# MKW41Z4 register map
Vendor: Freescale Semiconductor, Inc.; Series: Kinetis_W; File version: 1.6
CPU: CM0PLUS r0p0, little endian, no MPU, no FPU, VTOR, 2 interrupt priority bits
Registers are 16-bit, read-write, no defined reset value unless marked. A register's access mark holds for its fields unless they carry their own. Offsets are from the block's base; [hi:lo] are bit positions; {n}, {i} and the like mark numbered series; 'fields as' and 'values as' point back to an identical list.

## TSI0 — Touch sense input
Base 0x40045000; register names take the prefix TSI0_
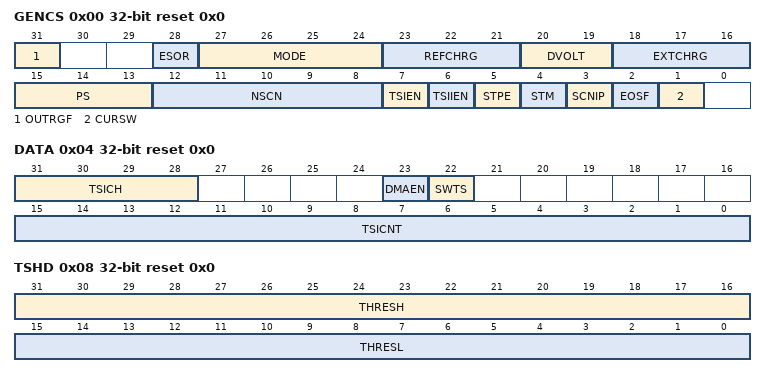
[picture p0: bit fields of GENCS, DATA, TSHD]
0x00 GENCS 32-bit reset 0x0 — TSI General Control and Status Register
  [31] OUTRGF — Out of Range Flag.
  [28] ESOR — End-of-scan or Out-of-Range Interrupt Selection
    0=Out-of-range interrupt is allowed; 1=End-of-scan interrupt is allowed
  [27:24] MODE — TSI analog modes setup and status bits.
    0=Set TSI in capacitive sensing(non-noise detection) mode; 4=Set TSI analog to work in single threshold noise detection mode and the frequency limitation circuit is disabled; 8=Set TSI analog to work in single threshold noise detection mode and the frequency limitation circuit is enabled to work in higher frequencies operations; 12=Set TSI analog to work in automatic noise detection mode
  [23:21] REFCHRG
    0=500 nA; 1=1 uA; 2=2 uA; 3=4 uA; 4=8 uA; 5=16 uA; 6=32 uA; 7=64 uA
  [20:19] DVOLT
    0=DV = 1.026 V; VP = 1.328 V; Vm = 0.302 V; 1=DV = 0.592 V; VP = 1.111 V; Vm = 0.519 V; 2=DV = 0.342 V; VP = 0.986 V; Vm = 0.644 V; 3=DV = 0.197 V; VP = 0.914 V; Vm = 0.716 V
  [18:16] EXTCHRG
    values as REFCHRG
  [15:13] PS
    0=Electrode Oscillator Frequency divided by 1; 1=Electrode Oscillator Frequency divided by 2; 2=Electrode Oscillator Frequency divided by 4; 3=Electrode Oscillator Frequency divided by 8; 4=Electrode Oscillator Frequency divided by 16; 5=Electrode Oscillator Frequency divided by 32; 6=Electrode Oscillator Frequency divided by 64; 7=Electrode Oscillator Frequency divided by 128
  [12:8] NSCN
    0=Once per electrode; 1=Twice per electrode; {v}={v+1} times per electrode (v=2..31)
  [7] TSIEN — Touch Sensing Input Module Enable
    0=TSI module disabled; 1=TSI module enabled
  [6] TSIIEN — Touch Sensing Input Interrupt Enable
    0=TSI interrupt is disabled; 1=TSI interrupt is enabled
  [5] STPE — TSI STOP Enable
    0=TSI is disabled when MCU goes into low power mode; 1=Allows TSI to continue running in all low power modes
  [4] STM — Scan Trigger Mode
    0=Software trigger scan; 1=Hardware trigger scan
  [3] SCNIP ro — Scan In Progress Status
    0=No scan in progress; 1=Scan in progress
  [2] EOSF — End of Scan Flag
    0=Scan not complete; 1=Scan complete
  [1] CURSW
    0=The current source pair are not swapped; 1=The current source pair are swapped
0x04 DATA 32-bit reset 0x0 — TSI DATA Register
  [31:28] TSICH
    {v}=Channel {v} (v=0..15)
  [23] DMAEN — DMA Transfer Enabled
    0=Interrupt is selected when the interrupt enable bit is set and the corresponding TSI events assert; 1=DMA transfer request is selected when the interrupt enable bit is set and the corresponding TSI events assert
  [22] SWTS wo — Software Trigger Start
    0=No effect; 1=Start a scan to determine which channel is specified by TSI_DATA[TSICH]
  [15:0] TSICNT ro — TSI Conversion Counter Value
0x08 TSHD 32-bit reset 0x0 — TSI Threshold Register
  [31:16] THRESH — TSI Wakeup Channel High-threshold
  [15:0] THRESL — TSI Wakeup Channel Low-threshold

## BTLE_RF_regs — BLE_RF
Base 0x4005B000
0x600 BLE_PART_ID ro reset 0x3 — BLUETOOTH LOW ENERGY PART ID
  [15:0] BLE_PART_ID
    0=Pre-production; 1=Pre-production; 2=KW40Z; 3=KW41Z
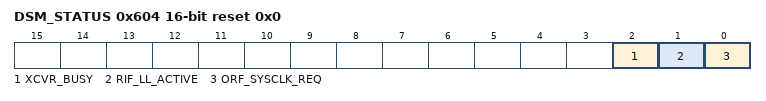
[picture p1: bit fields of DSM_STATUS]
0x604 DSM_STATUS ro reset 0x0 (reset mask 0xFFF8) — BLE DSM STATUS
  [2] XCVR_BUSY — Transceiver Busy Status Bit
    0=RF Channel in available (TSM is idle); 1=RF Channel in use (TSM is busy)
  [1] RIF_LL_ACTIVE — Link Layer Active
  [0] ORF_SYSCLK_REQ — RF Oscillator Requested
0x608 MISC_CTRL reset 0x0 — BLUETOOTH LOW ENERGY MISCELLANEOUS CONTROL
  [1] TSM_INTR_EN — TSM Interrupt Enable
    0=a TSM Interrupt during a BLE TX or RX sequence will not set bit [8] of BLE EVENT_STATUS; 1=a TSM Interrupt during a BLE TX or RX sequence will set bit [8] of BLE EVENT_STATUS
